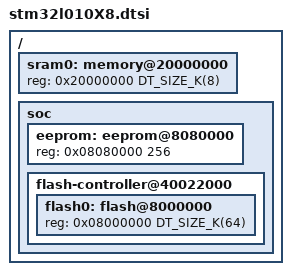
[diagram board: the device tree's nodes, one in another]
/*
 * Copyright (c) 2023 OS Systems
 *
 * SPDX-License-Identifier: Apache-2.0
 */

#include <mem.h>
#include <st/l0/stm32l010.dtsi>

/ {
	sram0: memory@20000000 {
		reg = <0x20000000 DT_SIZE_K(8)>;
	};

	soc {
		eeprom: eeprom@8080000{
			reg = <0x08080000 256>;
		};

		flash-controller@40022000 {
			flash0: flash@8000000 {
				reg = <0x08000000 DT_SIZE_K(64)>;
			};
		};
	};
};
